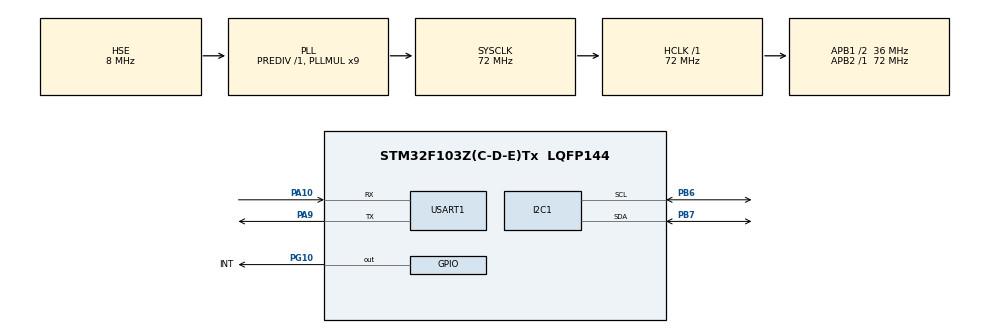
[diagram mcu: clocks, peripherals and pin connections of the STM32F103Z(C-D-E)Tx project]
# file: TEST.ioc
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Mcu.Family=STM32F1
Mcu.Name=STM32F103Z(C-D-E)Tx
Mcu.Package=LQFP144
NVIC.PriorityGroup=NVIC_PRIORITYGROUP_4
OSC_IN.Mode=HSE-External-Oscillator
OSC_IN.Signal=RCC_OSC_IN
OSC_OUT.Mode=HSE-External-Oscillator
OSC_OUT.Signal=RCC_OSC_OUT
PA10.Mode=Asynchronous
PA10.Signal=USART1_RX
PA13.Mode=Serial_Wire
PA13.Signal=SYS_JTMS-SWDIO
PA14.Mode=Serial_Wire
PA14.Signal=SYS_JTCK-SWCLK
PA9.Mode=Asynchronous
PA9.Signal=USART1_TX
PB6.Mode=I2C
PB6.Signal=I2C1_SCL
PB7.Mode=I2C
PB7.Signal=I2C1_SDA
PG10.GPIO_Label=INT
PG10.Signal=GPIO_Output
ProjectManager.HeapSize=0x200
ProjectManager.StackSize=0x400
ProjectManager.TargetToolchain=Makefile
RCC.AHBFreq_Value=72000000
RCC.APB1CLKDivider=RCC_HCLK_DIV2
RCC.APB1Freq_Value=36000000
RCC.APB1TimFreq_Value=72000000
RCC.APB2Freq_Value=72000000
RCC.APB2TimFreq_Value=72000000
RCC.HCLKFreq_Value=72000000
RCC.PLLMUL=RCC_PLL_MUL9
RCC.PLLSourceVirtual=RCC_PLLSOURCE_HSE
RCC.SYSCLKFreq_VALUE=72000000
RCC.SYSCLKSource=RCC_SYSCLKSOURCE_PLLCLK
RCC.USBFreq_Value=72000000
USART1.VirtualMode=VM_ASYNC
board=custom

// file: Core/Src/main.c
/* USER CODE BEGIN Header */
/**
  ******************************************************************************
  * @file           : main.c
  * @brief          : Main program body
  ******************************************************************************
  * @attention
  *
  * Copyright (c) 2022 STMicroelectronics.
  * All rights reserved.
  *
  * This software is licensed under terms that can be found in the LICENSE file
  * in the root directory of this software component.
  * If no LICENSE file comes with this software, it is provided AS-IS.
  *
  ******************************************************************************
  */
/* USER CODE END Header */
#include "main.h"
#include "i2c.h"
#include "usart.h"
#include "gpio.h"

/* USER CODE BEGIN Includes */
#include "retarget.h"
#include "bsp_includes.h"
#include "app_includes.h"
/* USER CODE END Includes */

void SystemClock_Config(void);

/* USER CODE BEGIN 0 */

UWORD cdc_now = 0; //the color temperature
/* USER CODE END 0 */

int main(void)
{
  /* USER CODE BEGIN 1 */
  light_t test = {0};
  test.pdata1 = &data1;
  test.pdata2 = &data2;

  /* USER CODE END 1 */

  /* MCU Configuration--------------------------------------------------------*/

  /* Reset of all peripherals, Initializes the Flash interface and the Systick. */
  HAL_Init();

  /* Configure the system clock */
  SystemClock_Config();

  /* Initialize all configured peripherals */
  MX_GPIO_Init();
  MX_USART1_UART_Init();
  MX_I2C1_Init();
  /* USER CODE BEGIN 2 */
  RetargetInit(&huart1);
  DEV_ModuleInit();

  /* USER CODE END 2 */

  /* Infinite loop */
  /* USER CODE BEGIN WHILE */
  Device_Init();
  while (1)
  {
    /* USER CODE END WHILE */
    My_Getdata_test(&test);
    test.light_attrs.cdc = TemCalculate(*(test.pdata1), *(test.pdata2));
    Calcute_Ra(&test);

  }
}

void SystemClock_Config(void)
{
  RCC_OscInitTypeDef RCC_OscInitStruct = {0};
  RCC_ClkInitTypeDef RCC_ClkInitStruct = {0};

  /** Initializes the RCC Oscillators according to the specified parameters
  * in the RCC_OscInitTypeDef structure.
  */
  RCC_OscInitStruct.OscillatorType = RCC_OSCILLATORTYPE_HSE;
  RCC_OscInitStruct.HSEState = RCC_HSE_ON;
  RCC_OscInitStruct.HSEPredivValue = RCC_HSE_PREDIV_DIV1;
  RCC_OscInitStruct.HSIState = RCC_HSI_ON;
  RCC_OscInitStruct.PLL.PLLState = RCC_PLL_ON;
  RCC_OscInitStruct.PLL.PLLSource = RCC_PLLSOURCE_HSE;
  RCC_OscInitStruct.PLL.PLLMUL = RCC_PLL_MUL9;
  if (HAL_RCC_OscConfig(&RCC_OscInitStruct) != HAL_OK)
  {
    Error_Handler();
  }

  /** Initializes the CPU, AHB and APB buses clocks
  */
  RCC_ClkInitStruct.ClockType = RCC_CLOCKTYPE_HCLK|RCC_CLOCKTYPE_SYSCLK
                              |RCC_CLOCKTYPE_PCLK1|RCC_CLOCKTYPE_PCLK2;
  RCC_ClkInitStruct.SYSCLKSource = RCC_SYSCLKSOURCE_PLLCLK;
  RCC_ClkInitStruct.AHBCLKDivider = RCC_SYSCLK_DIV1;
  RCC_ClkInitStruct.APB1CLKDivider = RCC_HCLK_DIV2;
  RCC_ClkInitStruct.APB2CLKDivider = RCC_HCLK_DIV1;

  if (HAL_RCC_ClockConfig(&RCC_ClkInitStruct, FLASH_LATENCY_2) != HAL_OK)
  {
    Error_Handler();
  }
}

void Error_Handler(void)
{
  __disable_irq();
  while (1)
  {
  }
}
